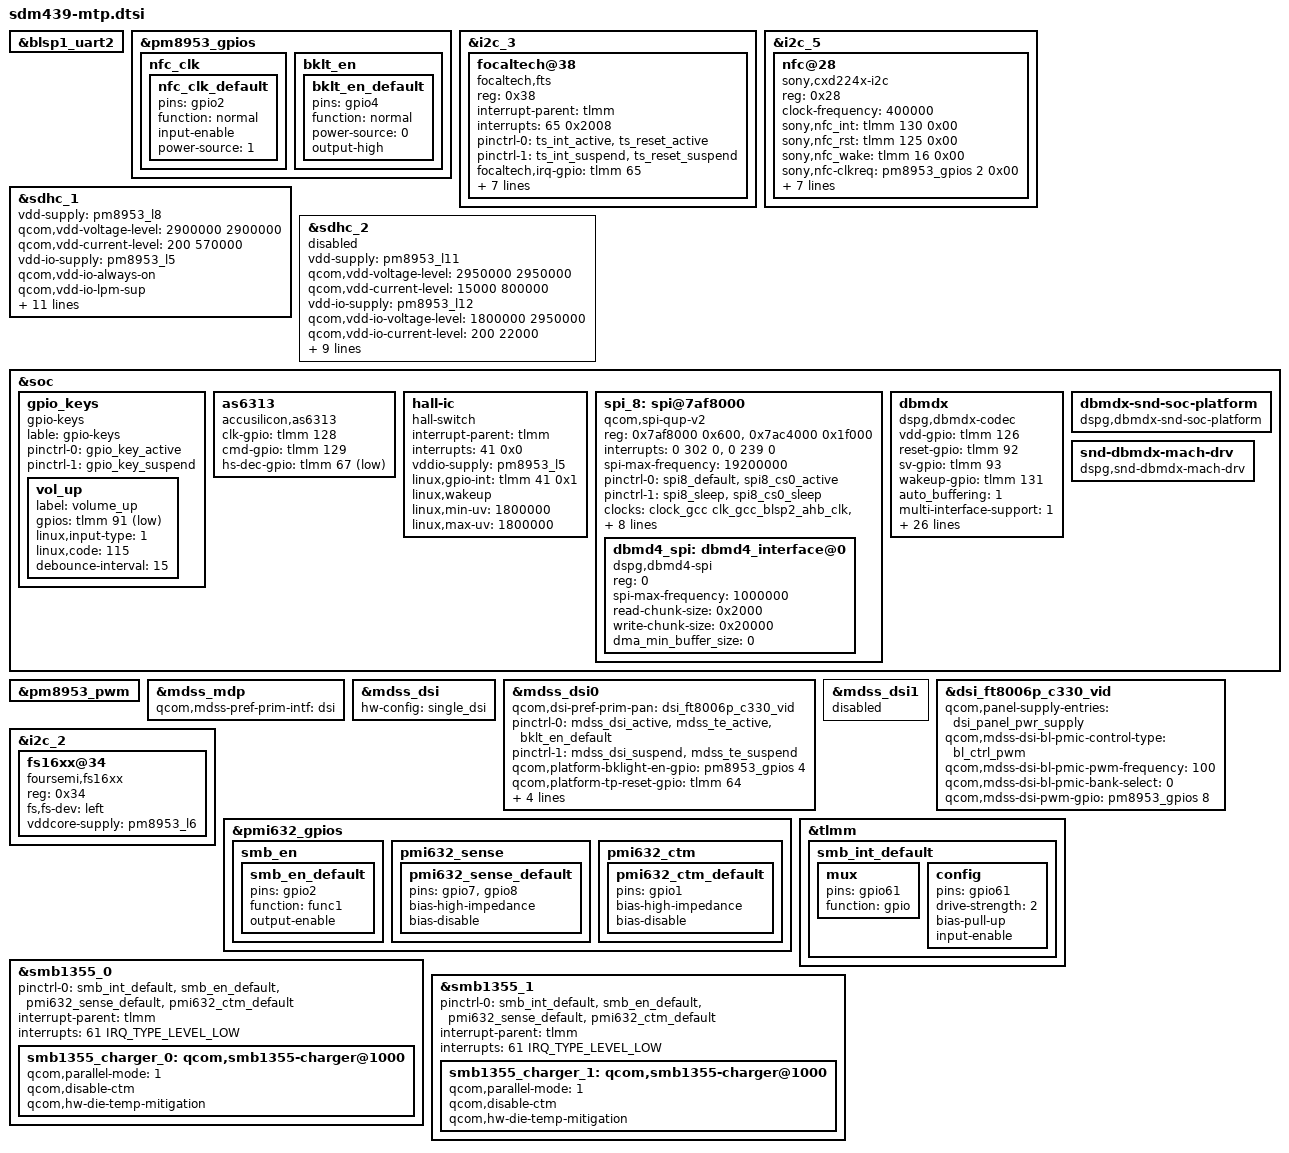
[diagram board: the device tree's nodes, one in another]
/*
 * Copyright (c) 2018, The Linux Foundation. All rights reserved.
 *
 * This program is free software; you can redistribute it and/or modify
 * it under the terms of the GNU General Public License version 2 and
 * only version 2 as published by the Free Software Foundation.
 *
 * This program is distributed in the hope that it will be useful,
 * but WITHOUT ANY WARRANTY; without even the implied warranty of
 * MERCHANTABILITY or FITNESS FOR A PARTICULAR PURPOSE.  See the
 * GNU General Public License for more details.
 */

#include "sdm439-camera-sensor-mtp.dtsi"

&blsp1_uart2 {
	status = "ok";
};

&pm8953_gpios {
	nfc_clk {
		nfc_clk_default: nfc_clk_default {
			pins = "gpio2";
			function = "normal";
			input-enable;
			power-source = <1>;
		};
	};
};

// add i2c3 for touchpanel
&i2c_3{
	status = "ok";
	focaltech@38 {
		compatible = "focaltech,fts";
		reg = <0x38>;
		interrupt-parent = <&tlmm>;
		interrupts = <65 0x2008>;
//		vdd-supply = <&pm8953_l10>;
//		vcc_i2c-supply = <&pm8953_l6>;
		/* pins used by touchscreen */
		pinctrl-names = "pmx_ts_active","pmx_ts_suspend";//,"pmx_ts_release";
		pinctrl-0 = <&ts_int_active &ts_reset_active>;
		pinctrl-1 = <&ts_int_suspend &ts_reset_suspend>;
		//pinctrl-2 = <&ts_release>;
		focaltech,irq-gpio = <&tlmm 65 0x0>;
		focaltech,reset-gpio = <&tlmm 64 0x0>;
		focaltech,max-touch-number = <5>;
		focaltech,display-coords = <0 0 720 1280>;
//get the chip type from file focaltech_config.h
//#define _FT3427             0x34270402
//demo code for further usage
//		focaltech,chiptype = <0x34270402>;
//		focaltech,have-key;
		focaltech,key-number = <3>;
		focaltech,keys = <139 102 158>;
		focaltech,key-y-coord = <2000>;
		focaltech,key-x-coords = <200 600 800>;
//		focaltech,multi-vendor-with-same-ic;
//		focaltech,tp_forceupgrade-deviceid = <0x54>;
//		focaltech,fw-auto-update;
//		focaltech,display-cfg-auto-update;
//		focaltech,esdcheck-enable;
//		focaltech,support-tp-gesture;
//		focaltech,enable-debug-log;
	};
};
&i2c_5 { /* BLSP2 QUP1 (NFC) */
	status = "ok";
//	nq@28 {
//		compatible = "qcom,nq-nci";
//		reg = <0x28>;
//		qcom,nq-irq = <&tlmm 17 0x00>;
//		qcom,nq-ven = <&tlmm 16 0x00>;
//		qcom,nq-firm = <&tlmm 130 0x00>;
//		qcom,nq-clkreq = <&pm8953_gpios 2 0x00>;
//		qcom,nq-esepwr = <&tlmm 93 0x00>;
//		interrupt-parent = <&tlmm>;
//		qcom,clk-src = "BBCLK2";
//		interrupts = <17 0>;
//		interrupt-names = "nfc_irq";
//		pinctrl-names = "nfc_active", "nfc_suspend";
//		pinctrl-0 = <&nfc_int_active &nfc_disable_active
//						&nfc_clk_default>;
//		pinctrl-1 = <&nfc_int_suspend &nfc_disable_suspend>;
//		clocks = <&clock_gcc clk_bb_clk2_pin>;
//		clock-names = "ref_clk";
//	};
	nfc@28 {
		compatible = "sony,cxd224x-i2c";
		status = "ok";
		reg = <0x28>;
		clock-frequency = <400000>;
		sony,nfc_int = <&tlmm 130 0x00>;
		sony,nfc_rst = <&tlmm 125 0x00>;
		sony,nfc_wake = <&tlmm 16 0x00>;
		sony,nfc-clkreq = <&pm8953_gpios 2 0x00>;
		interrupt-parent = <&tlmm>;
		qcom,clk-src = "BBCLK2";
		interrupts = <130 2>;  /* 1 = low-to-high edge triggered
					2 = high-to-low edge triggered
					4 = active high level-sensitive
					8 = active low level-sensitive */
		interrupt-names = "nfc_irq";
		pinctrl-names = "nfc_active";
		pinctrl-0 = <&nfc_gpio130_default &nfc_gpio125_default
						&nfc_gpio16_active &nfc_clk_default>;
		clocks = <&clock_gcc clk_bb_clk2_pin>;
		clock-names = "ref_clk";
	};
};

&sdhc_1 {
	/* device core power supply */
	vdd-supply = <&pm8953_l8>;
	qcom,vdd-voltage-level = <2900000 2900000>;
	qcom,vdd-current-level = <200 570000>;

	/* device communication power supply */
	vdd-io-supply = <&pm8953_l5>;
	qcom,vdd-io-always-on;
	qcom,vdd-io-lpm-sup;
	qcom,vdd-io-voltage-level = <1800000 1800000>;
	qcom,vdd-io-current-level = <200 325000>;

	pinctrl-names = "active", "sleep";
	pinctrl-0 = <&sdc1_clk_on &sdc1_cmd_on &sdc1_data_on &sdc1_rclk_on>;
	pinctrl-1 = <&sdc1_clk_off &sdc1_cmd_off &sdc1_data_off &sdc1_rclk_off>;

	qcom,clk-rates = <400000 20000000 25000000 50000000 100000000 192000000
								384000000>;
	qcom,nonremovable;
	qcom,bus-speed-mode = "HS400_1p8v", "HS200_1p8v", "DDR_1p8v";

	status = "ok";
};

&sdhc_2 {
	/* device core power supply */
	vdd-supply = <&pm8953_l11>;
	qcom,vdd-voltage-level = <2950000 2950000>;
	qcom,vdd-current-level = <15000 800000>;

	/* device communication power supply */
	vdd-io-supply = <&pm8953_l12>;
	qcom,vdd-io-voltage-level = <1800000 2950000>;
	qcom,vdd-io-current-level = <200 22000>;

	pinctrl-names = "active", "sleep";
	pinctrl-0 = <&sdc2_clk_on &sdc2_cmd_on &sdc2_data_on &sdc2_cd_on>;
	pinctrl-1 = <&sdc2_clk_off &sdc2_cmd_off &sdc2_data_off>;

	cd-gpios = <&tlmm 67 0x1>;

	qcom,clk-rates = <400000 20000000 25000000 50000000 100000000
								200000000>;
	qcom,bus-speed-mode = "SDR12", "SDR25", "SDR50", "DDR50", "SDR104";

	status = "disabled";
};

&soc {
	gpio_keys {
		compatible = "gpio-keys";
		lable = "gpio-keys";
		pinctrl-names = "tlmm_gpio_key_active","tlmm_gpio_key_suspend";
		pinctrl-0 = <&gpio_key_active>;
		pinctrl-1 = <&gpio_key_suspend>;
/*
		camera_focus {
			label = "camera_focus";
			gpios = <&tlmm 128 0x1>;
			linux,input-type = <1>;
			linux,code = <0x210>;
			debounce-interval = <15>;
			linux,can-disable;
			gpio-key,wakeup;
		};

		camera_snapshot {
			label = "camera_snapshot";
			gpios = <&tlmm 127 0x1>;
			linux,input-type = <1>;
			linux,code = <0x2fe>;
			debounce-interval = <15>;
			linux,can-disable;
			gpio-key,wakeup;
		};
*/
		vol_up {
			label = "volume_up";
			gpios = <&tlmm 91 0x1>;
			linux,input-type = <1>;
			linux,code = <115>;
			debounce-interval = <15>;
	//		linux,can-disable;
	//		gpio-key,wakeup;
		};
	};
	as6313 {
			compatible = "accusilicon,as6313";
			clk-gpio = <&tlmm 128 0>;
			cmd-gpio = <&tlmm 129 0>;
			hs-dec-gpio = <&tlmm 67 1>;
		};

	//wangyanhui add hall ic
	hall-ic{//yangliang add for hall sensor;20150902
		compatible = "hall-switch";
		//pinctrl-names = "default";
		//pinctrl-0 = <&hall_sensor_int_default>;
		interrupt-parent = <&tlmm>;
		interrupts = <41 0x0>;
		vddio-supply = <&pm8953_l5>;
		linux,gpio-int = <&tlmm 41 0x1>;
		linux,wakeup;
		linux,min-uv = <1800000>;
		linux,max-uv = <1800000>;
	};
};

#include "msm8937-mdss-panels.dtsi"

&pm8953_gpios {
	bklt_en {
		bklt_en_default: bklt_en_default {
		pins = "gpio4";
		function = "normal";
		power-source = <0>;
		output-high;
		};
	};
};

&pm8953_pwm {
	status = "ok";
};

&mdss_mdp {
	qcom,mdss-pref-prim-intf = "dsi";
};

&mdss_dsi {
	hw-config = "single_dsi";
};

&mdss_dsi0 {
	qcom,dsi-pref-prim-pan = <&dsi_ft8006p_c330_vid>;
	pinctrl-names = "mdss_default", "mdss_sleep";
	pinctrl-0 = <&mdss_dsi_active &mdss_te_active &bklt_en_default>;
	pinctrl-1 = <&mdss_dsi_suspend &mdss_te_suspend>;

	qcom,platform-bklight-en-gpio = <&pm8953_gpios 4 0>;
	qcom,platform-tp-reset-gpio = <&tlmm 64 0>;
	qcom,platform-te-gpio = <&tlmm 24 0>;
	qcom,platform-reset-gpio = <&tlmm 50 0>;
	lab-supply = <&lcdb_ldo_vreg>;
	ibb-supply = <&lcdb_ncp_vreg>;
};

&mdss_dsi1 {
	status = "disabled";
};

&dsi_ft8006p_c330_vid {
	qcom,panel-supply-entries = <&dsi_panel_pwr_supply>;
	qcom,mdss-dsi-bl-pmic-control-type = "bl_ctrl_pwm";
	qcom,mdss-dsi-bl-pmic-pwm-frequency = <100>;
	qcom,mdss-dsi-bl-pmic-bank-select = <0>;
	qcom,mdss-dsi-pwm-gpio = <&pm8953_gpios 8 0>;
	/delete-node/ qcom,mdss-dsi-display-timings;
};


&i2c_2 {
#include "smb1355.dtsi"
//lijian add for fs18xx
	fs16xx@34 {
		compatible = "foursemi,fs16xx";
		reg = <0x34>;
		fs,fs-dev = "left";
		vddcore-supply = <&pm8953_l6>;
		status = "okay";
	};
};

&pmi632_gpios {
	smb_en {
		smb_en_default: smb_en_default {
			pins = "gpio2";
			function = "func1";
			output-enable;
		};
	};

	pmi632_sense {
		/* GPIO 7 and 8 are external-sense pins for PMI632 */
		pmi632_sense_default: pmi632_sense_default {
			pins = "gpio7", "gpio8";
			bias-high-impedance;	/* disable the GPIO */
			bias-disable;		/* no-pull */
		};
	};

	pmi632_ctm {
		/* Disable GPIO1 for h/w base mitigation */
		pmi632_ctm_default: pmi632_ctm_default {
			pins = "gpio1";
			bias-high-impedance;	/* disable the GPIO */
			bias-disable;		/* no-pull */
		};
	};
};

&tlmm {
	smb_int_default: smb_int_default {
		mux {
			pins = "gpio61";
			function = "gpio";
		};
		config {
			pins = "gpio61";
			drive-strength = <2>;
			bias-pull-up;
			input-enable;
		};
	};
};

&smb1355_0 {
	pinctrl-names = "default";
	pinctrl-0 = <&smb_int_default
		&smb_en_default &pmi632_sense_default &pmi632_ctm_default>;
	interrupt-parent = <&tlmm>;
	interrupts = <61 IRQ_TYPE_LEVEL_LOW>;
	smb1355_charger_0: qcom,smb1355-charger@1000 {
		status ="ok";
		/delete-property/ io-channels;
		/delete-property/ io-channels-names;
		qcom,parallel-mode = <1>;
		qcom,disable-ctm;
		qcom,hw-die-temp-mitigation;
	};
};

&smb1355_1 {
	pinctrl-names = "default";
	pinctrl-0 = <&smb_int_default
		&smb_en_default &pmi632_sense_default &pmi632_ctm_default>;
	interrupt-parent = <&tlmm>;
	interrupts = <61 IRQ_TYPE_LEVEL_LOW>;
	smb1355_charger_1: qcom,smb1355-charger@1000 {
		status ="ok";
		/delete-property/ io-channels;
		/delete-property/ io-channels-names;
		qcom,parallel-mode = <1>;
		qcom,disable-ctm;
		qcom,hw-die-temp-mitigation;
	};
};



&soc {
	// #address-cells = <1>;
	// #size-cells = <1>;
	// ranges = <0 0 0 0xffffffff>;
	// compatible = "simple-bus";

	spi_8: spi@7af8000 { /* BLSP2 QUP3 */
		compatible = "qcom,spi-qup-v2";
		#address-cells = <1>;
		#size-cells = <0>;
		reg-names = "spi_physical", "spi_bam_physical";
		reg = <0x7af8000 0x600>,
			<0x7ac4000 0x1f000>;
		interrupt-names = "spi_irq", "spi_bam_irq";
		interrupts = <0 302 0>, <0 239 0>;
		spi-max-frequency = <19200000>;
		pinctrl-names = "spi_default", "spi_sleep";
		pinctrl-0 = <&spi8_default &spi8_cs0_active>;
		pinctrl-1 = <&spi8_sleep &spi8_cs0_sleep>;
		clocks = <&clock_gcc clk_gcc_blsp2_ahb_clk>,
			<&clock_gcc clk_gcc_blsp2_qup4_spi_apps_clk>;
		clock-names = "iface_clk", "core_clk";
		qcom,infinite-mode = <0>;
		qcom,use-bam;
		qcom,use-pinctrl;
		qcom,ver-reg-exists;
		qcom,bam-consumer-pipe-index = <10>;
		qcom,bam-producer-pipe-index = <11>;
		qcom,master-id = <84>;
		status = "ok";
	};
};




&spi_8 {
	status = "ok";
	pinctrl-names = "spi_default", "spi_sleep";
	pinctrl-0 = <&spi8_default &spi8_cs0_active>;
	pinctrl-1 = <&spi8_sleep &spi8_cs0_sleep>;

	dbmd4_spi: dbmd4_interface@0 {
		compatible = "dspg,dbmd4-spi";
		reg = <0>;
		spi-max-frequency = <1000000>;
		
		read-chunk-size  = <0x2000>;    /* 8192 bytes   */
		write-chunk-size = <0x20000>;   /* 131072 bytes */
		dma_min_buffer_size = <0>;
	};
};

&soc {
	dbmdx {
		compatible = "dspg,dbmdx-codec";
		vdd-gpio = <&tlmm 126 0>;  /* DBMD_EN VDD_CORE enable pin, Tinno added */
		reset-gpio = <&tlmm 92 0>; /* sensor header J53 connector */
		sv-gpio = <&tlmm 93 0>;    /* interrupt pin ? */
		wakeup-gpio = <&tlmm 131 0>;
	
		auto_buffering = <1>;
		multi-interface-support = <1>;
		cd-interfaces = <&dbmd4_spi >;
		va-interfaces = <0 0 0 0>;
		feature-va; /* enable VA */
		va-firmware-name = "dbmd4_va_fw.bin";
		va-config = <0x80000000
			     0x80000000
			     0x80000000
			     0x80290020
			     0x802200E0
			     0x80158E8E
			     0x801b0020
			     0x801A0011
			     0x80230000
			     0x8013FFF0
			     0x80107000
			     0x80000000
			     0x80000000
			     0x80000000>;

		va-speeds = <0x0000 460800  0 960000
			     0x0000 2000000 0 4800000
			     0x0000 3000000 0 4800000>;
		va-mic-config = <0xf041 0x1044 0x0008>; // <0xf041 0x1044 0x0028>
		va-mic-mode = <4>; // anlog=4, digital=0
		master-clk-rate = <32768>;
		/* constant-clk-rate = <32768>; */
		firmware_id = <0xdbd4>;
		use_gpio_for_wakeup = <1>; /* Use wakeup gpio */
		wakeup_set_value = <0>;  /* Value to write to wakeup gpio */
		auto_detection = <1>;
		detection_buffer_channels = <0>;
		min_samples_chunk_size = <128>;
		pcm_streaming_mode = <1>;
		boot_options = <0x200>; /* Verify chip id */
		send_uevent_on_detection = <1>;
		send_uevent_after_buffering = <1>;
		detection_after_buffering = <0>;
		va_backlog_length = <2>;
		va_backlog_length_okg = <1000>;
		amodel_options = <0>;
		analog_mic_analog_gain = <0x8a8a>;
	};

	dbmdx-snd-soc-platform {
		compatible = "dspg,dbmdx-snd-soc-platform";
	};

	snd-dbmdx-mach-drv {
		compatible = "dspg,snd-dbmdx-mach-drv";
	};
};
